# mcr_me21 register map
Registers are access not given, no defined reset value unless marked. A register's access mark holds for its fields unless they carry their own. Offsets are from the block's base; lines under a group give offsets from that group; [hi:lo] are bit positions; {n}, {i} and the like mark numbered series; 'fields as' and 'values as' point back to an identical list; <NAME> marks a mode.

## Memory map
0x40106C00 MCR size 0x400 — Misc Control.

## MCR — Misc Control.
Base 0x40106C00
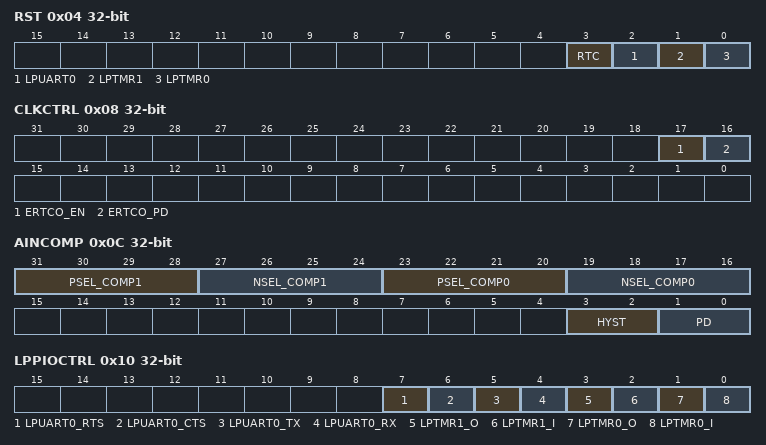
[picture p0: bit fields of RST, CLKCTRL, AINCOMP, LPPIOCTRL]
0x04 RST — Low Power Reset Control Register
  [all] fields
    0=reset_done (Reset complete.); 1=busy (Starts Reset or indicates reset in progress.)
  [3] RTC — RTC Reset.
  [2] LPUART0 — Low Power UART0 Reset.
  [1] LPTMR1 — Low Power Timer1 Reset.
  [0] LPTMR0 — Low Power Timer0 Reset.
0x08 CLKCTRL — Clock Control.
  [17] ERTCO_EN — 32KHz Crystal Oscillator Enable.
    0=dis (Is Disabled.); 1=en (Is Enabled.)
  [16] ERTCO_PD — 32KHz Crystal Oscillator Power Down.
0x0C AINCOMP — AIN Comparator.
  [31:28] PSEL_COMP1 — Positive input select for AIN Comparator 1
  [27:24] NSEL_COMP1 — Negative input select for AIN Comparator 1
  [23:20] PSEL_COMP0 — Positive input select for AIN Comparator 0
  [19:16] NSEL_COMP0 — Negative input select for AIN Comparator 0.
  [3:2] HYST — AIN Comparator Hysteresis control.
  [1:0] PD — AIN Comparator Power Down control.
0x10 LPPIOCTRL — Low Power Peripheral IO Control Register.
  [7] LPUART0_RTS — Enable control for LPUART0 RTS.
  [6] LPUART0_CTS — Enable control for LPUART0 CTS.
  [5] LPUART0_TX — Enable control for LPUART0 TX.
  [4] LPUART0_RX — Enable control for LPUART0 RX.
  [3] LPTMR1_O — Enable control for LPTMR1 output.
  [2] LPTMR1_I — Enable control for LPTMR1 input.
  [1] LPTMR0_O — Enable control for LPTMR0 output.
  [0] LPTMR0_I — Enable control for LPTMR0 input.
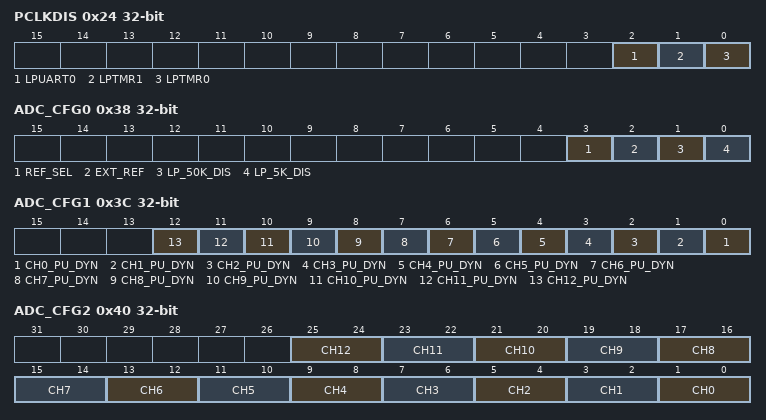
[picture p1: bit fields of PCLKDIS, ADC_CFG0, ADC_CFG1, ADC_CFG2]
0x24 PCLKDIS — Low Power Peripheral Clock Disable.
  [all] fields
    0=en (enable it.); 1=dis (disable it.)
  [2] LPUART0 — Low Power UART0 Clock Disable.
  [1] LPTMR1 — Low Power Timer1 Clock Disable.
  [0] LPTMR0 — Low Power Timer0 Clock Disable.
0x34 AESKEY — AES Key Pointer and Status.
  [15:0] PTR — AESKEY Pointer and Status.
0x38 ADC_CFG0 — ADC Cfig Register0.
  [3] REF_SEL — Reference Select
  [2] EXT_REF — External Reference
  [1] LP_50K_DIS — Disable 50K divider option in low power modes
    0=EN (Enable.); 1=DIS (Disable.)
  [0] LP_5K_DIS — Disable 5K divider option in low power modes
    0=en (Enable.); 1=dis (Disable.)
0x3C ADC_CFG1 — ADC Config Register1.
  [all] fields
    0=dis (divider select always used.); 1=en (divider select only used when channel is selected.)
  [n] CH{n}_PU_DYN (n=0..12) — ADC PU Dynamic Control for CH{n}
0x40 ADC_CFG2 — ADC Config Register2.
  [all] fields
    0=div1 (Pass through, no divider.); 1=div2_5k (Divide by 2, 5Kohm.); 2=div2_50k (Divide by 2, 50Kohm.)
  [2n+1:2n] CH{n} (n=0..12) — Divider Select for channel {n}
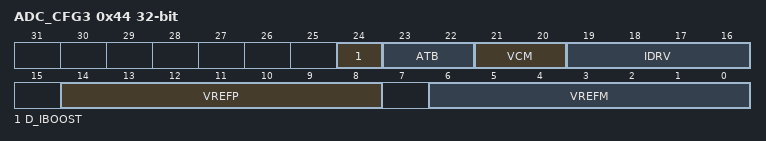
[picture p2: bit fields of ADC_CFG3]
0x44 ADC_CFG3 — ADC Config Register3.
  [24] D_IBOOST, [23:22] ATB, [21:20] VCM, [19:16] IDRV, [14:8] VREFP, [6:0] VREFM
